# S6E1B8xG register map
Vendor: Cypress; File version: 2.0
CPU: CM0PLUS r0p1, little endian, no MPU, no FPU, 2 interrupt priority bits
Registers are 8-bit, read-write, reset 0x0 unless marked. A register's access mark holds for its fields unless they carry their own. Offsets are from the block's base; [hi:lo] are bit positions.

## USBCLK — USB/Ethernet Clock
Base 0x40036000
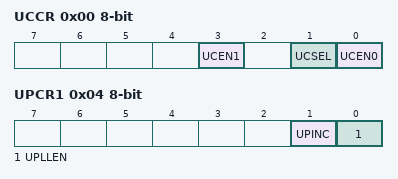
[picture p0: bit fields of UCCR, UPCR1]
0x00 UCCR — USB Clock Control Register
  [3] UCEN1 — USB1 clock output enable bit
  [1] UCSEL — USB clock selection bit
  [0] UCEN0 — USB0 clock output enable bit
0x04 UPCR1 — USB-PLL Control Register 1
  [1] UPINC — USB-PLL input clock selection bit
  [0] UPLLEN — USB-PLL oscillation enable bit
0x08 UPCR2 — USB-PLL Control Register 2
  [2:0] UPOWT — USB-PLL oscillation stabilization wait time setting bit
0x0C UPCR3 — USB-PLL Control Register 3
  [4:0] UPLLK — Frequency division ratio (K) setting bit of the USB-PLL clock
0x10 UPCR4 reset 0x3B — USB-PLL Control Register 4
  [6:0] UPLLN — Frequency division ratio (N) setting bit of the USB-PLL clock
0x14 UP_STR ro — USB-PLL Status Register
  [0] UPRDY — USB-PLL oscillation stabilization bit
0x18 UPINT_ENR — USB-PLL Interrupt Factor Enable Register
  [0] UPCSE — USB-PLL oscillation stabilization wait complete interrupt enable bit
0x1C UPINT_CLR wo — USB-PLL Interrupt Factor Clear Register
  [0] UPCSC — USB-PLL oscillation stabilization interrupt factor clear bit
0x20 UPINT_STR ro — USB-PLL Interrupt Factor Status Register
  [0] UPCSI — USB-PLL interrupt factor status bit
0x24 UPCR5 reset 0x4 — USB-PLL Control Register 5
  [3:0] UPLLM — Frequency division ratio (M) setting bit of the USB-PLL clock
0x30 USBEN0 — USB0 Enable Register
  [0] USBEN0 — USB0 enable bit
0x34 USBEN1 — USB1 Enable Register
  [0] USBEN1 — USB1 enable bit

## CRC — CRC Registers
Base 0x40039000
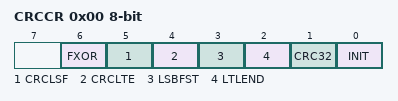
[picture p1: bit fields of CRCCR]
0x00 CRCCR — CRC Control Register
  [6] FXOR — Final XOR control bit
  [5] CRCLSF — CRC result bit-order setting bit
  [4] CRCLTE — CRC result byte-order setting bit
  [3] LSBFST — Bit-order setting bit
  [2] LTLEND — Byte-order setting bit
  [1] CRC32 — CRC mode selection bit
  [0] INIT — Initialization bit
0x04 CRCINIT 32-bit reset 0xFFFFFFFF — Initial Value Register
  [31:0] D — Initial value bits
0x08 CRCIN 32-bit — Input Data Register
  [31:0] D — Input data bits
0x0C CRCR 32-bit ro reset 0xFFFFFFFF — CRC Register
  [31:0] D — CRC bits

## WC — Watch Counter
Base 0x4003A000
0x00 WCRD ro — Watch Counter Read Register
  [5:0] CTR — Counter read bits
0x01 WCRL — Watch Counter Reload Register
  [5:0] RLC — Counter reload value setting bits
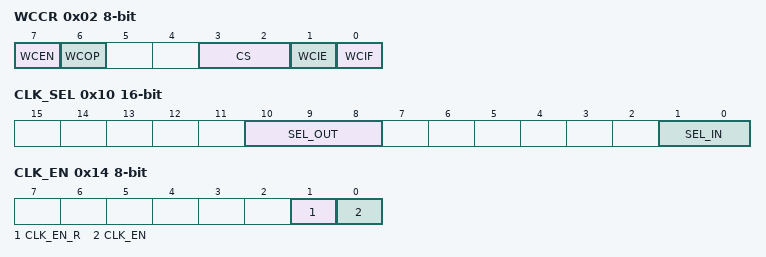
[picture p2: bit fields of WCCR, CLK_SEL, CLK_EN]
0x02 WCCR — Watch Counter Control Register
  [7] WCEN — Watch counter operation enable bit
  [6] WCOP ro — Watch counter operating state flag
  [3:2] CS — Count clock select bits
  [1] WCIE — Interrupt request enable bit
  [0] WCIF — Interrupt request flag bit
0x10 CLK_SEL 16-bit — Clock Selection Register
  [10:8] SEL_OUT — Output clock selection bit
  [1:0] SEL_IN — Input clock selection bit
0x14 CLK_EN — Division Clock Enable Register
  [1] CLK_EN_R — Division clock enable read bit
  [0] CLK_EN — Division clock enable bit

## LSCRP — Low-speed CR Prescaler Register
Base 0x4003C000
0x00 LCR_PRSLD — Low-speed CR Prescaler Control Register
  [5:0] LCR_PRSLD — Low-speed CR Prescaler Load

## CLK_GATING — Peripheral Clock Gating Registers
Base 0x4003C100
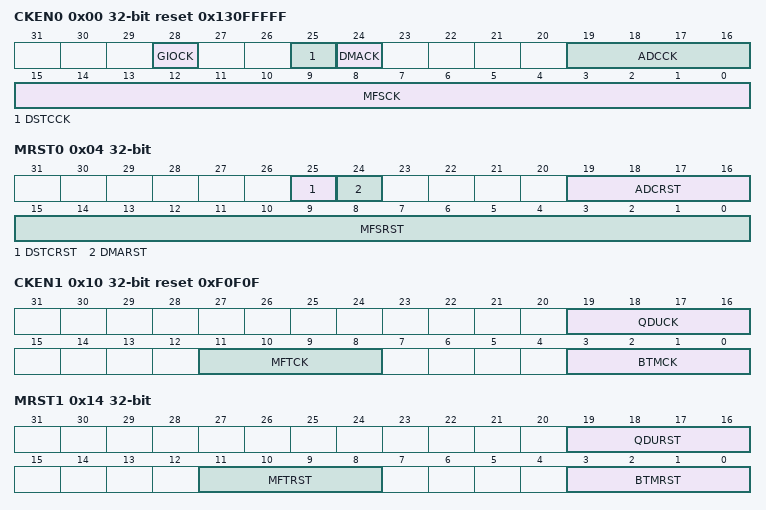
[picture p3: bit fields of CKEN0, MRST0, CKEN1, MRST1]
0x00 CKEN0 32-bit reset 0x130FFFFF — Peripheral Function Clock Control Register 0
  [28] GIOCK — Software clock control of GPIO/Fast GPIO function
  [25] DSTCCK — Software clock control of DSTC function
  [24] DMACK — Supplying and gating settings of DMAC operation clock
  [19:16] ADCCK — Settings for operation clock supplying and gating to A/D converters
  [15:0] MFSCK — Settings for operation clock supply and gating to multi-function serial interface
0x04 MRST0 32-bit — Peripheral Function Reset Control Register 0
  [25] DSTCRST — Reset control of DSTC
  [24] DMARST — Reset control of DMAC
  [19:16] ADCRST — Reset control of A/D converters
  [15:0] MFSRST — Control of software reset of multi-function serial interface ch.15
0x10 CKEN1 32-bit reset 0xF0F0F — Peripheral Function Clock Control Register 1
  [19:16] QDUCK — Settings for operation clock supply and gating of quad counters
  [11:8] MFTCK — Settings for operation clock supply and gating of multi-function timer and PPG
  [3:0] BTMCK — Settings operation clock supply and gating to base timers
0x14 MRST1 32-bit — Peripheral Function Reset Control Register 1
  [19:16] QDURST — Reset control of quad counters
  [11:8] MFTRST — Control of multi-function timer and PPG reset control
  [3:0] BTMRST — Reset control of base timers
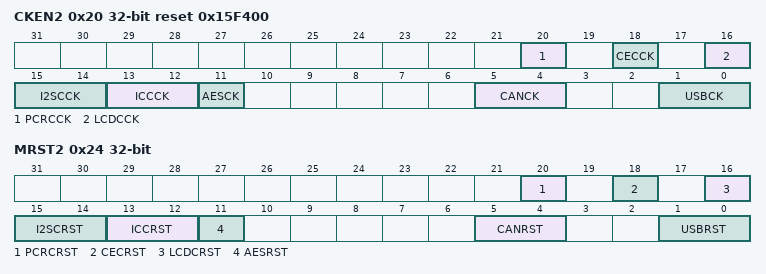
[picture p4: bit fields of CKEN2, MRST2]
0x20 CKEN2 32-bit reset 0x15F400 (reset mask 0x15F403) — Peripheral Function Clock Control Register 2
  [20] PCRCCK — Settings for clock supply and gating to Programmable-CRC
  [18] CECCK — Settings for clock supply and gating of HDMI-CEC/Remote Control Reception
  [16] LCDCCK — Settings for clock supply and gating to LCD Controller
  [15:14] I2SCCK — Settings for clock supply and gating of MFSI2S
  [13:12] ICCCK — Settings for clock supply and gating of IC-Card Interface
  [11] AESCK — Settings for clock supply and gating to AES
  [5:4] CANCK ro — Settings for clock supply and gating to CAN controller
  [1:0] USBCK — Settings for clock supply and gating of USB
0x24 MRST2 32-bit (reset mask 0x15F433) — Peripheral Function Reset Control Register 2
  [20] PCRCRST — Reset control of Programmable-CRC
  [18] CECRST — Reset control of HDMI-CEC/Remote Control Reception
  [16] LCDCRST — Reset control of LCD Controller
  [15:14] I2SCRST — Reset control of MFSI2S
  [13:12] ICCRST — Reset control of IC-Card Interface
  [11] AESRST — Reset control of AES
  [5:4] CANRST — Reset control of CAN controller
  [1:0] USBRST — Reset control of USB

## Notices in the file
Copyright (C) 2013-2015, Cypress Semiconductor Corporation. All Rights Reserved.
This software, including source code, documentation and related
materials ( "Software" ), is owned by Cypress Semiconductor
Corporation ( "Cypress" ) and is protected by and subject to worldwide
patent protection (United States and foreign), United States copyright
laws and international treaty provisions. Therefore, you may use this
Software only as provided in the license agreement accompanying the
software package from which you obtained this Software ( "EULA" ).
If no EULA applies, Cypress hereby grants you a personal, nonexclusive,
non-transferable license to copy, modify, and compile the
Software source code solely for use in connection with Cypress's
integrated circuit products. Any reproduction, modification, translation,
compilation, or representation of this Software except as specified
above is prohibited without the express written permission of Cypress.
Disclaimer: THIS SOFTWARE IS PROVIDED AS-IS, WITH NO
WARRANTY OF ANY KIND, EXPRESS OR IMPLIED, INCLUDING,
BUT NOT LIMITED TO, NONINFRINGEMENT, IMPLIED
WARRANTIES OF MERCHANTABILITY AND FITNESS FOR A
PARTICULAR PURPOSE. Cypress reserves the right to make
changes to the Software without notice. Cypress does not assume any
liability arising out of the application or use of the Software or any
product or circuit described in the Software. Cypress does not
authorize its products for use in any products where a malfunction or
failure of the Cypress product may reasonably be expected to result in
significant property damage, injury or death ( "High Risk Product" ). By
including Cypress's product in a High Risk Product, the manufacturer
of such system or application assumes all risk of such use and in doing
so agrees to indemnify Cypress against all liability.
